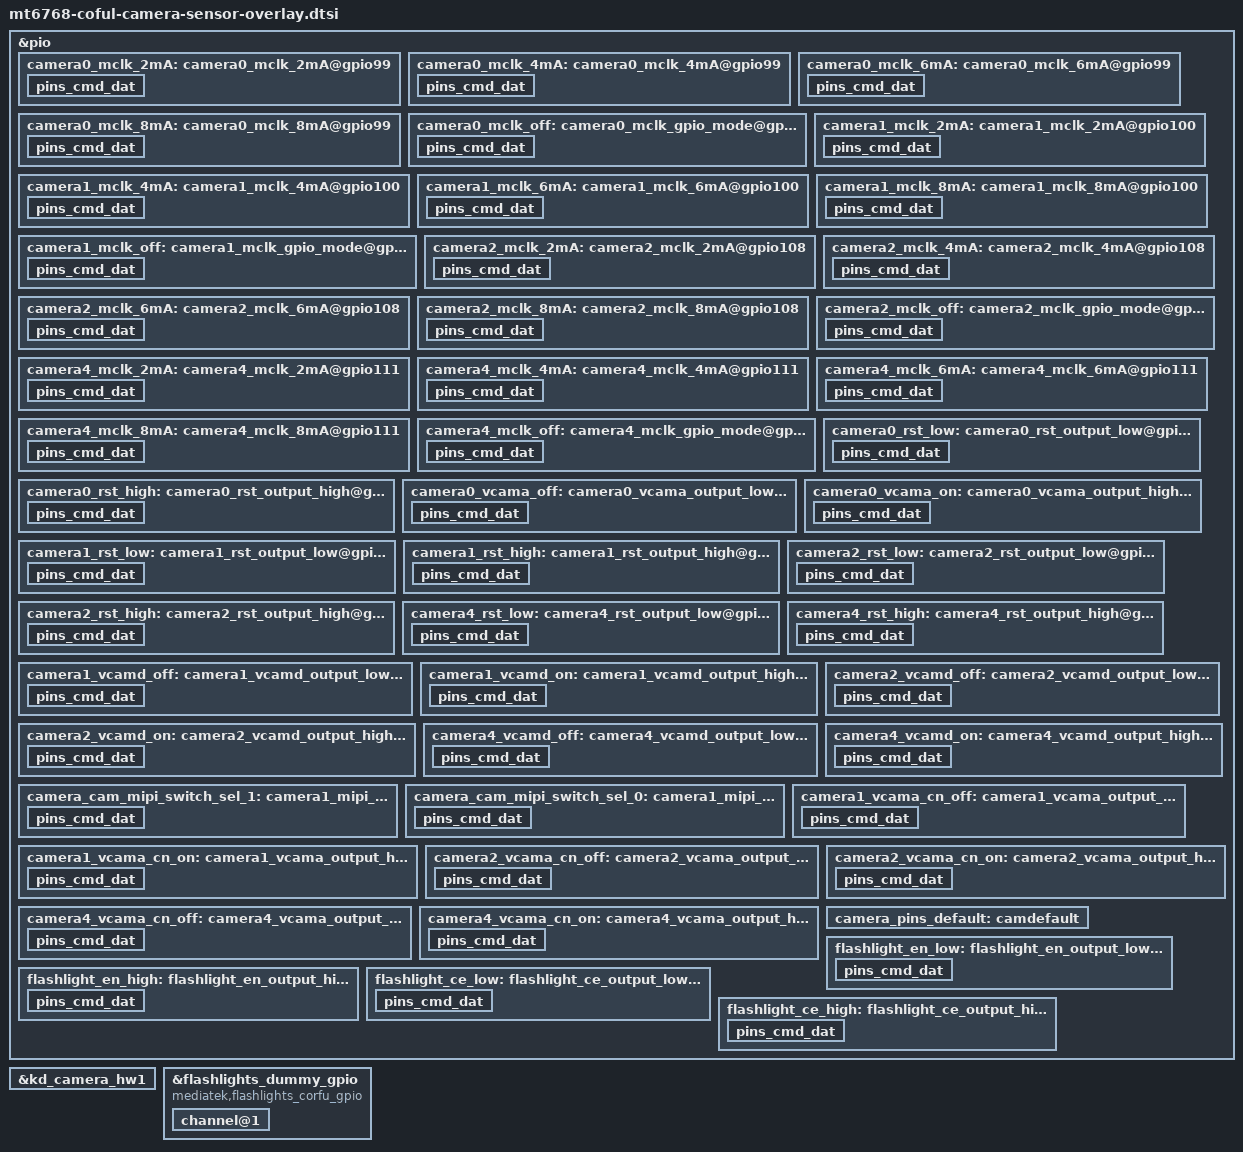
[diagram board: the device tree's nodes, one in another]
/*
 * Copyright (c) 2019 MediaTek Inc.
 *
 * This program is free software; you can redistribute it and/or modify
 * it under the terms of the GNU General Public License version 2 as
 * published by the Free Software Foundation.
 *
 * This program is distributed in the hope that it will be useful,
 * but WITHOUT ANY WARRANTY; without even the implied warranty of
 * MERCHANTABILITY or FITNESS FOR A PARTICULAR PURPOSE.  See the
 * GNU General Public License for more details.
 */
/* CAMERA GPIO standardization */
&pio {
	camera0_mclk_2mA: camera0_mclk_2mA@gpio99 {
		pins_cmd_dat {
			pinmux = <PINMUX_GPIO99__FUNC_CMMCLK0>;
			drive-strength = <MTK_DRIVE_2mA>;
		};
	};
	camera0_mclk_4mA: camera0_mclk_4mA@gpio99 {
		pins_cmd_dat {
			pinmux = <PINMUX_GPIO99__FUNC_CMMCLK0>;
			drive-strength = <MTK_DRIVE_4mA>;
		};
	};
	camera0_mclk_6mA: camera0_mclk_6mA@gpio99 {
		pins_cmd_dat {
			pinmux = <PINMUX_GPIO99__FUNC_CMMCLK0>;
			drive-strength = <MTK_DRIVE_6mA>;
		};
	};
	camera0_mclk_8mA: camera0_mclk_8mA@gpio99 {
		pins_cmd_dat {
			pinmux = <PINMUX_GPIO99__FUNC_CMMCLK0>;
			drive-strength = <7>;
		};
	};
	camera0_mclk_off: camera0_mclk_gpio_mode@gpio99 {
		pins_cmd_dat {
			pinmux = <PINMUX_GPIO99__FUNC_GPIO99>;
			drive-strength = <MTK_DRIVE_4mA>;
		};
	};
	camera1_mclk_2mA: camera1_mclk_2mA@gpio100 {
		pins_cmd_dat {
			pinmux = <PINMUX_GPIO100__FUNC_CMMCLK1>;
			drive-strength = <MTK_DRIVE_2mA>;
		};
	};
	camera1_mclk_4mA: camera1_mclk_4mA@gpio100 {
		pins_cmd_dat {
			pinmux = <PINMUX_GPIO100__FUNC_CMMCLK1>;
			drive-strength = <MTK_DRIVE_4mA>;
		};
	};
	camera1_mclk_6mA: camera1_mclk_6mA@gpio100 {
		pins_cmd_dat {
			pinmux = <PINMUX_GPIO100__FUNC_CMMCLK1>;
			drive-strength = <MTK_DRIVE_6mA>;
		};
	};
	camera1_mclk_8mA: camera1_mclk_8mA@gpio100 {
		pins_cmd_dat {
			pinmux = <PINMUX_GPIO100__FUNC_CMMCLK1>;
			drive-strength = <7>;
		};
	};
	camera1_mclk_off: camera1_mclk_gpio_mode@gpio100 {
		pins_cmd_dat {
			pinmux = <PINMUX_GPIO100__FUNC_GPIO100>;
			drive-strength = <MTK_DRIVE_4mA>;
		};
	};
	camera2_mclk_2mA: camera2_mclk_2mA@gpio108 {
		pins_cmd_dat {
			pinmux = <PINMUX_GPIO108__FUNC_CMMCLK2>;
			drive-strength = <MTK_DRIVE_2mA>;
		};
	};
	camera2_mclk_4mA: camera2_mclk_4mA@gpio108 {
		pins_cmd_dat {
			pinmux = <PINMUX_GPIO108__FUNC_CMMCLK2>;
			drive-strength = <MTK_DRIVE_4mA>;
		};
	};
	camera2_mclk_6mA: camera2_mclk_6mA@gpio108 {
		pins_cmd_dat {
			pinmux = <PINMUX_GPIO108__FUNC_CMMCLK2>;
			drive-strength = <MTK_DRIVE_6mA>;
		};
	};
	camera2_mclk_8mA: camera2_mclk_8mA@gpio108 {
		pins_cmd_dat {
			pinmux = <PINMUX_GPIO108__FUNC_CMMCLK2>;
			drive-strength = <7>;
		};
	};
	camera2_mclk_off: camera2_mclk_gpio_mode@gpio108 {
		pins_cmd_dat {
			pinmux = <PINMUX_GPIO108__FUNC_GPIO108>;
			drive-strength = <MTK_DRIVE_4mA>;
		};
	};
	camera4_mclk_2mA: camera4_mclk_2mA@gpio111 {
		pins_cmd_dat {
			pinmux = <PINMUX_GPIO111__FUNC_CMMCLK3>;
			drive-strength = <MTK_DRIVE_2mA>;
		};
	};
	camera4_mclk_4mA: camera4_mclk_4mA@gpio111 {
		pins_cmd_dat {
			pinmux = <PINMUX_GPIO111__FUNC_CMMCLK3>;
			drive-strength = <MTK_DRIVE_4mA>;
		};
	};
	camera4_mclk_6mA: camera4_mclk_6mA@gpio111 {
		pins_cmd_dat {
			pinmux = <PINMUX_GPIO111__FUNC_CMMCLK3>;
			drive-strength = <MTK_DRIVE_6mA>;
		};
	};
	camera4_mclk_8mA: camera4_mclk_8mA@gpio111 {
		pins_cmd_dat {
			pinmux = <PINMUX_GPIO111__FUNC_CMMCLK3>;
			drive-strength = <7>;
		};
	};
	camera4_mclk_off: camera4_mclk_gpio_mode@gpio111 {
		pins_cmd_dat {
			pinmux = <PINMUX_GPIO111__FUNC_GPIO111>;
			drive-strength = <MTK_DRIVE_4mA>;
		};
	};
	camera0_rst_low: camera0_rst_output_low@gpio101 {
		pins_cmd_dat {
			pinmux = <PINMUX_GPIO101__FUNC_GPIO101>;
			output-low;
		};
	};
	camera0_rst_high: camera0_rst_output_high@gpio101 {
		pins_cmd_dat {
			pinmux = <PINMUX_GPIO101__FUNC_GPIO101>;
			output-high;
		};
	};
    camera0_vcama_off: camera0_vcama_output_low@gpio97 {
		pins_cmd_dat {
			pinmux = <PINMUX_GPIO97__FUNC_GPIO97>;
			output-low;
		};
	};
	camera0_vcama_on: camera0_vcama_output_high@gpio97 {
		pins_cmd_dat {
			pinmux = <PINMUX_GPIO97__FUNC_GPIO97>;
			output-high;
		};
	};
	camera1_rst_low: camera1_rst_output_low@gpio102 {
		pins_cmd_dat {
			pinmux = <PINMUX_GPIO102__FUNC_GPIO102>;
			output-low;
		};
	};
	camera1_rst_high: camera1_rst_output_high@gpio102 {
		pins_cmd_dat {
			pinmux = <PINMUX_GPIO102__FUNC_GPIO102>;
			output-high;
		};
	};
	camera2_rst_low: camera2_rst_output_low@gpio109 {
		pins_cmd_dat {
			pinmux = <PINMUX_GPIO109__FUNC_GPIO109>;
			output-low;
		};
	};
	camera2_rst_high: camera2_rst_output_high@gpio109 {
		pins_cmd_dat {
			pinmux = <PINMUX_GPIO109__FUNC_GPIO109>;
			output-high;
		};
	};
	camera4_rst_low: camera4_rst_output_low@gpio98 {
		pins_cmd_dat {
			pinmux = <PINMUX_GPIO98__FUNC_GPIO98>;
			output-low;
		};
	};
	camera4_rst_high: camera4_rst_output_high@gpio98 {
		pins_cmd_dat {
			pinmux = <PINMUX_GPIO98__FUNC_GPIO98>;
			output-high;
		};
	};
	camera1_vcamd_off: camera1_vcamd_output_low@gpio178 {
		pins_cmd_dat {
			pinmux = <PINMUX_GPIO178__FUNC_GPIO178>;
			output-low;
		};
	};
	camera1_vcamd_on: camera1_vcamd_output_high@gpio178 {
		pins_cmd_dat {
			pinmux = <PINMUX_GPIO178__FUNC_GPIO178>;
			output-high;
		};
	};
	camera2_vcamd_off: camera2_vcamd_output_low@gpio107 {
		pins_cmd_dat {
			pinmux = <PINMUX_GPIO107__FUNC_GPIO107>;
			output-low;
		};
	};
	camera2_vcamd_on: camera2_vcamd_output_high@gpio107 {
		pins_cmd_dat {
			pinmux = <PINMUX_GPIO107__FUNC_GPIO107>;
			output-high;
		};
	};
	camera4_vcamd_off: camera4_vcamd_output_low@gpio152 {
		pins_cmd_dat {
			pinmux = <PINMUX_GPIO152__FUNC_GPIO152>;
			output-low;
		};
	};
	camera4_vcamd_on: camera4_vcamd_output_high@gpio152 {
		pins_cmd_dat {
			pinmux = <PINMUX_GPIO152__FUNC_GPIO152>;
			output-high;
		};
	};
	camera_cam_mipi_switch_sel_1: camera1_mipi_switch_output_high@gpio152 {
		pins_cmd_dat {
			pinmux = <PINMUX_GPIO152__FUNC_GPIO152>;
			output-high;
		};
	};
	camera_cam_mipi_switch_sel_0: camera1_mipi_switch_output_low@gpio152 {
		pins_cmd_dat {
			pinmux = <PINMUX_GPIO152__FUNC_GPIO152>;
			output-low;
		};
	};
	camera1_vcama_cn_off: camera1_vcama_output_low@gpio92 {
		pins_cmd_dat {
			pinmux = <PINMUX_GPIO92__FUNC_GPIO92>;
			output-low;
		};
	};
	camera1_vcama_cn_on: camera1_vcama_output_high@gpio92 {
		pins_cmd_dat {
			pinmux = <PINMUX_GPIO92__FUNC_GPIO92>;
			output-high;
		};
	};
	camera2_vcama_cn_off: camera2_vcama_output_low@gpio165 {
		pins_cmd_dat {
			pinmux = <PINMUX_GPIO165__FUNC_GPIO165>;
			output-low;
		};
	};
	camera2_vcama_cn_on: camera2_vcama_output_high@gpio165 {
		pins_cmd_dat {
			pinmux = <PINMUX_GPIO165__FUNC_GPIO165>;
			output-high;
		};
	};
	camera4_vcama_cn_off: camera4_vcama_output_low@gpio153{
		pins_cmd_dat {
			pinmux = <PINMUX_GPIO153__FUNC_GPIO153>;
			output-low;
		};
	};
	camera4_vcama_cn_on: camera4_vcama_output_high@gpio153 {
		pins_cmd_dat {
			pinmux = <PINMUX_GPIO153__FUNC_GPIO153>;
			output-high;
		};
	};
	camera_pins_default: camdefault {
	};

};

&kd_camera_hw1 {
	pinctrl-names = "default",
			"cam0_rst0", "cam0_rst1",
			"cam1_rst0", "cam1_rst1",
			"cam2_rst0", "cam2_rst1",
			"cam4_rst0", "cam4_rst1",
            		"cam0_vcama_on",
			"cam0_vcama_off",
			"cam1_vcamd_on",
			"cam1_vcamd_off",
			"cam2_vcamd_on",
			"cam2_vcamd_off",
			"cam4_vcamd_on",
			"cam4_vcamd_off",
			"cam0_mclk_off",
			"cam0_mclk_2mA", "cam0_mclk_4mA",
			"cam0_mclk_6mA", "cam0_mclk_8mA",
			"cam1_mclk_off",
			"cam1_mclk_2mA", "cam1_mclk_4mA",
			"cam1_mclk_6mA", "cam1_mclk_8mA",
			"cam2_mclk_off",
			"cam2_mclk_2mA", "cam2_mclk_4mA",
			"cam2_mclk_6mA", "cam2_mclk_8mA",
			"cam4_mclk_off",
			"cam4_mclk_2mA", "cam4_mclk_4mA",
			"cam4_mclk_6mA", "cam4_mclk_8mA",
			"cam_mipi_switch_sel_1",
			"cam_mipi_switch_sel_0",
            		"cam1_vcama_cn_on",
			"cam1_vcama_cn_off",
            		"cam2_vcama_cn_on",
			"cam2_vcama_cn_off",
            		"cam4_vcama_cn_on",
			"cam4_vcama_cn_off";

	pinctrl-0 = <&camera_pins_default>;
	pinctrl-1 = <&camera0_rst_low>;
	pinctrl-2 = <&camera0_rst_high>;
	pinctrl-3 = <&camera1_rst_low>;
	pinctrl-4 = <&camera1_rst_high>;
	pinctrl-5 = <&camera2_rst_low>;
	pinctrl-6 = <&camera2_rst_high>;
	pinctrl-7 = <&camera4_rst_low>;
	pinctrl-8 = <&camera4_rst_high>;
	pinctrl-9 = <&camera0_vcama_on>;
	pinctrl-10 = <&camera0_vcama_off>;
	pinctrl-11 = <&camera1_vcamd_on>;
	pinctrl-12 = <&camera1_vcamd_off>;
	pinctrl-13 = <&camera2_vcamd_on>;
	pinctrl-14 = <&camera2_vcamd_off>;
	pinctrl-15= <&camera4_vcamd_on>;
	pinctrl-16 = <&camera4_vcamd_off>;
	pinctrl-17 = <&camera0_mclk_off>;
	pinctrl-18 = <&camera0_mclk_2mA>;
	pinctrl-19 = <&camera0_mclk_4mA>;
	pinctrl-20 = <&camera0_mclk_6mA>;
	pinctrl-21 = <&camera0_mclk_8mA>;
	pinctrl-22 = <&camera1_mclk_off>;
	pinctrl-23 = <&camera1_mclk_2mA>;
	pinctrl-24 = <&camera1_mclk_4mA>;
	pinctrl-25 = <&camera1_mclk_6mA>;
	pinctrl-26 = <&camera1_mclk_8mA>;
	pinctrl-27 = <&camera2_mclk_off>;
	pinctrl-28 = <&camera2_mclk_2mA>;
	pinctrl-29 = <&camera2_mclk_4mA>;
	pinctrl-30 = <&camera2_mclk_6mA>;
	pinctrl-31 = <&camera2_mclk_8mA>;
	pinctrl-32 = <&camera4_mclk_off>;
	pinctrl-33 = <&camera4_mclk_2mA>;
	pinctrl-34 = <&camera4_mclk_4mA>;
	pinctrl-35 = <&camera4_mclk_6mA>;
	pinctrl-36 = <&camera4_mclk_8mA>;
    	pinctrl-37 = <&camera_cam_mipi_switch_sel_1>;
	pinctrl-38 = <&camera_cam_mipi_switch_sel_0>;
	pinctrl-39 = <&camera1_vcama_cn_on>;
	pinctrl-40 = <&camera1_vcama_cn_off>;
	pinctrl-41 = <&camera2_vcama_cn_on>;
	pinctrl-42 = <&camera2_vcama_cn_off>;
	pinctrl-43 = <&camera4_vcama_cn_on>;
	pinctrl-44 = <&camera4_vcama_cn_off>;

	cam0_vcamd-supply = <&mt_pmic_vcamd_ldo_reg>;
	cam0_vcamio-supply = <&mt_pmic_vcamio_ldo_reg>;
	cam1_vcama-supply = <&mt_pmic_vcama2_ldo_reg>;
	cam2_vcama-supply = <&mt_pmic_vcama1_ldo_reg>;
	cam4_vcama-supply = <&mt_pmic_vcama2_ldo_reg>;
	cam1_vcamio-supply = <&mt_pmic_vcamio_ldo_reg>;
	cam2_vcamio-supply = <&mt_pmic_vcamio_ldo_reg>;
	cam4_vcamio-supply = <&mt_pmic_vcamio_ldo_reg>;

	cam0_enable_sensor = "mot_coful_s5kjn1_qtech";
	cam1_enable_sensor = "mot_corfu_hi1336_ofilm";
	cam2_enable_sensor = "mot_coful_s5k4h7_qtech";
	cam4_enable_sensor = "mot_coful_gc02m1_tsp";
	cust-sensor = "mot_coful_s5kjn1_qtech mot_corfu_hi1336_ofilm mot_coful_s5k4h7_qtech mot_coful_gc02m1_tsp";

	status = "okay";

};
/* CAMERA GPIO end */
/* flashlight gpio start*/
&pio {
	flashlight_en_low: flashlight_en_output_low@gpio160 {
		pins_cmd_dat {
			pinmux = <PINMUX_GPIO160__FUNC_GPIO160>;
			output-low;
		};
	};
	flashlight_en_high: flashlight_en_output_high@gpio160 {
		pins_cmd_dat {
			pinmux = <PINMUX_GPIO160__FUNC_GPIO160>;
			output-high;
		};
	};
	flashlight_ce_low: flashlight_ce_output_low@gpio159 {
		pins_cmd_dat {
			pinmux = <PINMUX_GPIO159__FUNC_GPIO159>;
			output-low;
		};
	};
	flashlight_ce_high: flashlight_ce_output_high@gpio159 {
		pins_cmd_dat {
			pinmux = <PINMUX_GPIO159__FUNC_GPIO159>;
			output-high;
		};
	};
};

&flashlights_dummy_gpio {
	compatible = "mediatek,flashlights_corfu_gpio";
	pinctrl-names = "flashlight_en_low",
			"flashlight_en_high",
			"flashlight_ce_low",
			"flashlight_ce_high";

	pinctrl-0 = <&flashlight_en_low>;
	pinctrl-1 = <&flashlight_en_high>;
	pinctrl-2 = <&flashlight_ce_low>;
	pinctrl-3 = <&flashlight_ce_high>;

	decouple = <1>;
	channel@1 {
		type = <0>;
		ct = <0>;
		part = <0>;
	};
};
/* flashlight gpio end*/

